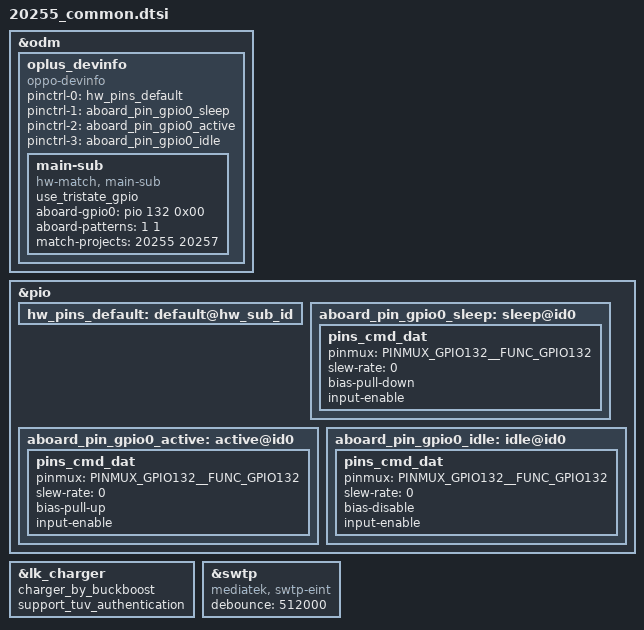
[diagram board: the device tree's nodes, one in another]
&odm {
        oplus_devinfo:oplus_devinfo {
                compatible = "oppo-devinfo";
                pinctrl-names = "default", "aboard_gpio0_sleep", "aboard_gpio0_active", "aboard_gpio0_idle";
                pinctrl-0 = <&hw_pins_default>;
                pinctrl-1 = <&aboard_pin_gpio0_sleep>;
                pinctrl-2 = <&aboard_pin_gpio0_active>;
                pinctrl-3 = <&aboard_pin_gpio0_idle>;
                main-sub {
                        use_tristate_gpio;
                        compatible = "hw-match, main-sub";
                        aboard-gpio0 = <&pio 132 0x00>;
                        aboard-patterns = <1 1>;        /*0[high-resistance] 1[pull-down] 2[pull-up]*/
                        /*main board*/
                        match-projects = <20255 20257>;
                };
        };
};
&pio {
        hw_pins_default:default@hw_sub_id {
        };

        aboard_pin_gpio0_sleep:sleep@id0 {
                pins_cmd_dat {
                        pinmux = <PINMUX_GPIO132__FUNC_GPIO132>;
                        slew-rate = <0>;
                        bias-pull-down;
                        input-enable;
                };
        };

        aboard_pin_gpio0_active:active@id0 {
                pins_cmd_dat {
                        pinmux = <PINMUX_GPIO132__FUNC_GPIO132>;
                        slew-rate = <0>;
                        bias-pull-up;
                        input-enable;
                };
        };

        aboard_pin_gpio0_idle:idle@id0 {
                pins_cmd_dat {
                        pinmux = <PINMUX_GPIO132__FUNC_GPIO132>;
                        slew-rate = <0>;
                        bias-disable;
                        input-enable;
                };
        };
};
/*#endif OPLUS_FEATURE_TP_BASIC*/
//#ifdef OPLUS_FEATURE_CHG_BASIC
&lk_charger{
	charger_by_buckboost;
	support_tuv_authentication;
};
//#endif

//#ifdef OPLUS_FEATURE_SWTP
&swtp {
	compatible = "mediatek, swtp-eint";
	debounce = <512000>;
};
//#endif
